# MU3E_ORDERED_PRIORITY_QUEUE_NATIVE_SV_FIXED4 register map
Vendor: Mu3e; Series: MU3E_FPGA_IP; File version: 26.5.3.0517
CMSIS-SVD description of the fixed-profile 4-lane native-SV OPQ CSR aperture used by the SWB integration. BaseAddress is 0 because this file describes the relative IP aperture; system integration supplies the live slave base address.
Registers are 32-bit, read-only, reset 0x0 unless marked. A register's access mark holds for its fields unless they carry their own. Offsets are from the block's base; lines under a group give offsets from that group; [hi:lo] are bit positions; {n}, {i} and the like mark numbered series; 'fields as' and 'values as' point back to an identical list; <NAME> marks a mode.

## Memory map
0x00000000 ORDERED_PRIORITY_QUEUE_FIXED4_CSR size 0x800 — Relative CSR aperture for the fixed4 native-SV ordered priority queue wrapper. Register offsets are byte offsets matching the RTL word-addressed Avalon-MM map multiplied by four.

## ORDERED_PRIORITY_QUEUE_FIXED4_CSR — Relative CSR aperture for the fixed4 native-SV ordered priority queue wrapper. Register offsets are byte offsets matching the RTL word-addressed Avalon-MM map multiplied by four.
Base 0x00000000
0x00 UID reset 0x4F50514D — Software-visible IP identifier. Default ASCII "OPQM".
  [31:0] value — Compile-time or integration-time UID word. Default ASCII "OPQM".
0x04 META rw — Read-multiplexed metadata word. Write [1:0] selects VERSION, DATE, GIT, or INSTANCE_ID; reads return the selected page payload.
  [31:0] page_sel_or_payload — Writes use [1:0] as the metadata page selector; reads return the selected 32-bit payload.
0x08 LANE_MASK rw — Software lane mask applied at packet boundaries. Low four bits are implemented.
  [3:0] lane_mask — Bit i masks lane i after the in-flight packet drains.
0x0C CTRL wo — Write-only control pulses.
  [0] clear_counters rw write-1-sets — Write one to clear all software-visible counters, including parser-visible ingress frame and subframe counters.
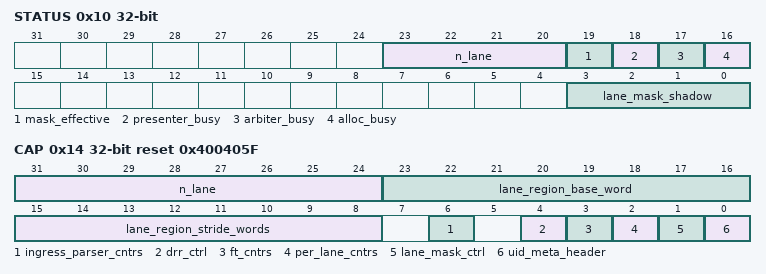
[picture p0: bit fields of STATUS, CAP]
0x10 STATUS — Lane-mask shadow, busy flags, effective-mask status, and fixed lane count.
  [23:20] n_lane — Instantiated lane count, fixed at four for this wrapper.
  [19] mask_effective — At least one lane is currently blocked at the packet-boundary mask gate.
  [18] presenter_busy — Egress presenter has a valid beat pending or in flight.
  [17] arbiter_busy — Page-RAM write-port arbiter is active.
  [16] alloc_busy — Page allocator is active.
  [3:0] lane_mask_shadow — Software-programmed lane mask shadow.
0x14 CAP reset 0x400405F — Capability summary and CSR lane-region geometry.
  [31:24] n_lane — Number of instantiated ingress lanes, fixed at four.
  [23:16] lane_region_base_word — Base word address of the per-lane CSR region. Current RTL returns 0x40.
  [15:8] lane_region_stride_words — Per-lane CSR region stride in 32-bit words. Current RTL returns 0x10.
  [6] ingress_parser_cntrs — Parser-visible frame and subframe counters are implemented at words 0x140 and 0x150.
  [4] drr_ctrl — DRR allowance programming and observability are implemented.
  [3] ft_cntrs — Frame-table counters are implemented.
  [2] per_lane_cntrs — Per-lane counters are implemented.
  [1] lane_mask_ctrl — Software lane masking is implemented.
  [0] uid_meta_header — Common Mu3e UID and META header is implemented.
0x20 FT_WR_HDR — Headers committed into frame-table ownership.
  [31:0] value
0x24 FT_WR_SHD — Subheaders committed into frame-table ownership.
  [31:0] value
0x28 FT_WR_HIT — Hits committed into frame-table ownership.
  [31:0] value
0x2C FT_RD_HDR — Headers retired through the egress presenter.
  [31:0] value
0x30 FT_RD_SHD — Subheaders retired through the egress presenter.
  [31:0] value
0x34 FT_RD_HIT — Hits retired through the egress presenter.
  [31:0] value
0x38 FT_DROP_HDR — Headers dropped by frame-table overwrite or overwrite recovery.
  [31:0] value
0x3C FT_DROP_SHD — Subheaders dropped by frame-table overwrite or overwrite recovery.
  [31:0] value
0x40 FT_DROP_HIT — Hits dropped by frame-table overwrite or overwrite recovery.
  [31:0] value
{0x100+0x40*i} LANE{i}_WR_HDR_CNT (i=0..3) — Headers accepted from ingress parsing.
  [31:0] value
{0x104+0x40*i} LANE{i}_WR_SHD_CNT (i=0..3) — Subheaders accepted from ingress parsing.
  [31:0] value
{0x108+0x40*i} LANE{i}_WR_HIT_CNT (i=0..3) — Hit words written into the lane FIFO.
  [31:0] value
{0x10C+0x40*i} LANE{i}_RD_HDR_CNT (i=0..3) — Headers consumed by the page allocator.
  [31:0] value
{0x110+0x40*i} LANE{i}_RD_SHD_CNT (i=0..3) — Subheaders accepted into the merged page stream.
  [31:0] value
{0x114+0x40*i} LANE{i}_RD_HIT_CNT (i=0..3) — Hits accepted into the merged page stream.
  [31:0] value
{0x118+0x40*i} LANE{i}_DROP_HDR_CNT (i=0..3) — Headers dropped before frame-table ownership.
  [31:0] value
{0x11C+0x40*i} LANE{i}_DROP_SHD_CNT (i=0..3) — Subheaders dropped before frame-table ownership.
  [31:0] value
{0x120+0x40*i} LANE{i}_DROP_HIT_CNT (i=0..3) — Hits dropped before frame-table ownership.
  [31:0] value
{0x124+0x40*i} LANE{i}_LANE_FREE_CREDIT (i=0..3) — Live lane-FIFO free-credit word.
  [31:0] value
{0x128+0x40*i} LANE{i}_TICKET_FREE_CREDIT (i=0..3) — Live ticket-FIFO free-credit word.
  [31:0] value
{0x12C+0x40*i} LANE{i}_DRR_ALLOWANCE rw (i=0..3) — Software-programmed DRR refill allowance in page words.
  [9:0] value
{0x130+0x40*i} LANE{i}_DRR_QUANTUM_LIVE (i=0..3) — Live DRR deficit budget.
  [9:0] value
{0x134+0x40*i} LANE{i}_DRR_GRANT_CNT (i=0..3) — Block-level arbiter grant count.
  [31:0] value
{0x138+0x40*i} LANE{i}_DRR_BEAT_CNT (i=0..3) — Page-RAM data beats served from this lane.
  [31:0] value
{0x13C+0x40*i} LANE{i}_DRR_DEFER_CNT (i=0..3) — Defer rounds while this lane requested service without enough budget.
  [31:0] value
{0x500+4i} INGRESS_FRAME_CNT_LANE{i} (i=0..3) — Saturating parser-visible legal frame SOP count for this lane, counted after the OPQ lane mask and before allocator, credit, or drop decisions.
  [31:0] value
{0x540+4i} INGRESS_SUBFRAME_CNT_LANE{i} (i=0..3) — Saturating parser-visible legal subframe/subheader count for this lane, including zero-hit subheaders before allocator, credit, or drop decisions.
  [31:0] value
